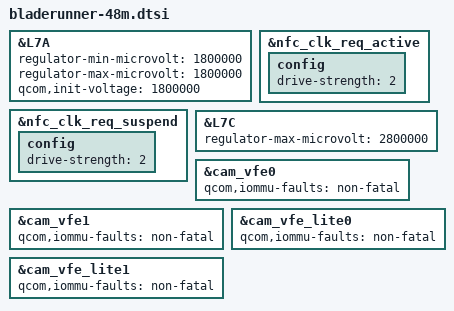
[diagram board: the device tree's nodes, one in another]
// kona-regulators.dtsi
&L7A {
    regulator-min-microvolt = <1800000>;
    regulator-max-microvolt = <1800000>;
    qcom,init-voltage = <1800000>;
};

// kona-pinctrl.dtsi
&nfc_clk_req_active {
    config {
        drive-strength = <2>; /* 2 MA */
    };
};

&nfc_clk_req_suspend {
    config {
        drive-strength = <2>; /* 2 MA */
    };
};

&L7C {
    regulator-max-microvolt = <2800000>;
};

// camera/kona-camera.dtsi
&cam_vfe0 {
    /* #ifdef VENDOR_EDIT */
    qcom,iommu-faults = "non-fatal";
    /* #endif*/
}; 

&cam_vfe1 {
    /* #ifdef VENDOR_EDIT */
    qcom,iommu-faults = "non-fatal";
    /* #endif*/
};

&cam_vfe_lite0 {
    /* #ifdef VENDOR_EDIT */
    qcom,iommu-faults = "non-fatal";
    /* #endif*/
};

&cam_vfe_lite1 {
    /* #ifdef VENDOR_EDIT */
    qcom,iommu-faults = "non-fatal";
    /* #endif*/
};
